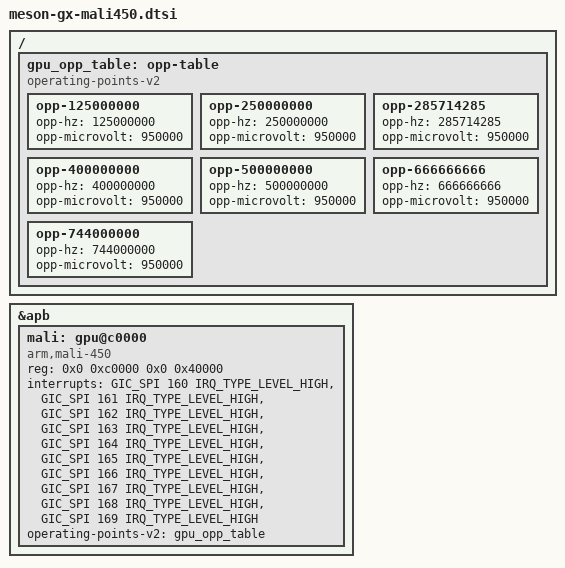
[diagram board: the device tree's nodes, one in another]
// SPDX-License-Identifier: (GPL-2.0+ OR MIT)
/*
 * Copyright (c) 2017 BayLibre SAS
 * Author: Neil Armstrong <narmstrong@baylibre.com>
 */

/ {
	gpu_opp_table: opp-table {
		compatible = "operating-points-v2";

		opp-125000000 {
			opp-hz = /bits/ 64 <125000000>;
			opp-microvolt = <950000>;
		};
		opp-250000000 {
			opp-hz = /bits/ 64 <250000000>;
			opp-microvolt = <950000>;
		};
		opp-285714285 {
			opp-hz = /bits/ 64 <285714285>;
			opp-microvolt = <950000>;
		};
		opp-400000000 {
			opp-hz = /bits/ 64 <400000000>;
			opp-microvolt = <950000>;
		};
		opp-500000000 {
			opp-hz = /bits/ 64 <500000000>;
			opp-microvolt = <950000>;
		};
		opp-666666666 {
			opp-hz = /bits/ 64 <666666666>;
			opp-microvolt = <950000>;
		};
		opp-744000000 {
			opp-hz = /bits/ 64 <744000000>;
			opp-microvolt = <950000>;
		};
	};
};

&apb {
	mali: gpu@c0000 {
		compatible = "arm,mali-450";
		reg = <0x0 0xc0000 0x0 0x40000>;
		interrupts = <GIC_SPI 160 IRQ_TYPE_LEVEL_HIGH>,
			     <GIC_SPI 161 IRQ_TYPE_LEVEL_HIGH>,
			     <GIC_SPI 162 IRQ_TYPE_LEVEL_HIGH>,
			     <GIC_SPI 163 IRQ_TYPE_LEVEL_HIGH>,
			     <GIC_SPI 164 IRQ_TYPE_LEVEL_HIGH>,
			     <GIC_SPI 165 IRQ_TYPE_LEVEL_HIGH>,
			     <GIC_SPI 166 IRQ_TYPE_LEVEL_HIGH>,
			     <GIC_SPI 167 IRQ_TYPE_LEVEL_HIGH>,
			     <GIC_SPI 168 IRQ_TYPE_LEVEL_HIGH>,
			     <GIC_SPI 169 IRQ_TYPE_LEVEL_HIGH>;
		interrupt-names = "gp", "gpmmu", "pp", "pmu",
			"pp0", "ppmmu0", "pp1", "ppmmu1",
			"pp2", "ppmmu2";
		operating-points-v2 = <&gpu_opp_table>;
	};
};
